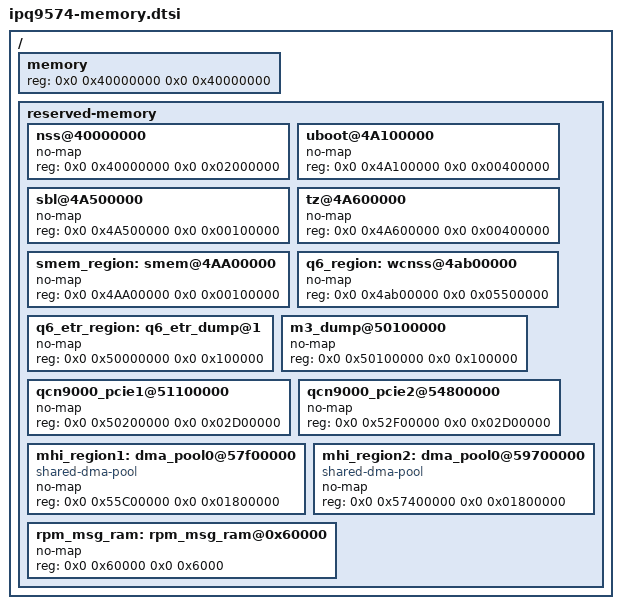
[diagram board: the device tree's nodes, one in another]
// SPDX-License-Identifier: (GPL-2.0+ OR BSD-3-Clause)
/*
 * IPQ9048 Memory device tree source
 *
 * Copyright (c) 2021 The Linux Foundation. All rights reserved.
 */

/ {

	/*		  Default Profile
	 * +=========+==============+========================+
	 * |        |              |                         |
	 * | Region | Start Offset |          Size           |
	 * |        |              |                         |
	 * +--------+--------------+-------------------------+
	 * |        |              |                         |
	 * |  NSS   |  0x40000000  |          32MB           |
	 * |        |              |                         |
	 * +--------+--------------+-------------------------+
	 * |        |              |                         |
	 * |        |              |                         |
	 * |        |              |                         |
	 * |        |              |                         |
	 * | Linux  |  0x42000000  |         129MB           |
	 * |        |              |                         |
	 * |        |              |                         |
	 * |        |              |                         |
	 * +--------+--------------+-------------------------+
	 * |        |              |                         |
	 * | uboot  |  0x4A100000  |           4MB           |
	 * |        |              |                         |
	 * +--------+--------------+-------------------------+
	 * |  SBL   |  0x4A500000  |           1MB           |
	 * +--------+--------------+-------------------------+
	 * |        |              |                         |
	 * | TZ+HYP |  0x4A600000  |           4MB           |
	 * |        |              |                         |
	 * +--------+--------------+-------------------------+
	 * |  smem  |  0x4AA00000  |           1MB           |
	 * +--------+--------------+-------------------------+
	 * |        |              |                         |
	 * |        |              |                         |
	 * | WLAN   |              |                         |
	 * |   Q6   |  0x4AB00000  |          85MB           |
	 * |        |              |                         |
	 * |        |              |                         |
	 * +--------+--------------+-------------------------+
	 * | WLAN   |              |                         |
	 * | Q6 ETR |  0x50000000  |           1MB           |
	 * | Region |              |                         |
	 * +--------+--------------+-------------------------+
	 * | M3 Dump|  0x50100000  |           1MB           |
	 * +--------+--------------+-------------------------+
	 * |        |              |                         |
	 * |  Pine1 |  0x50200000  |          45MB           |
	 * |        |              |                         |
	 * +--------+--------------+-------------------------+
	 * |        |              |                         |
	 * |  Pine2 |  0x52F00000  |          45MB           |
	 * |        |              |                         |
	 * +--------+--------------+-------------------------+
	 * |        |              |                         |
	 * |  MHI1  |  0x55C00000  |          24MB           |
	 * |        |              |                         |
	 * +--------+--------------+-------------------------+
	 * |        |              |                         |
	 * |  MHI2  |  0x57400000  |          24MB           |
	 * |        |              |                         |
	 * +=================================================+
	 * |                                                 |
	 * |                                                 |
	 * |                                                 |
	 * |            Rest of memory for Linux             |
	 * |                                                 |
	 * |                                                 |
	 * |                                                 |
	 * +=================================================+
	 */

	memory {
		device_type = "memory";
		reg = <0x0 0x40000000 0x0 0x40000000>;
	};

	reserved-memory {
		#address-cells = <2>;
		#size-cells = <2>;
		ranges;

		nss@40000000 {
			no-map;
			reg = <0x0 0x40000000 0x0 0x02000000>;
		};

		uboot@4A100000 {
			no-map;
			reg = <0x0 0x4A100000 0x0 0x00400000>;
		};

		sbl@4A500000 {
			no-map;
			reg = <0x0 0x4A500000 0x0 0x00100000>;
		};

		tz@4A600000 {
			no-map;
			reg = <0x0 0x4A600000 0x0 0x00400000>;
		};

		smem_region: smem@4AA00000 {
			no-map;
			reg = <0x0 0x4AA00000 0x0 0x00100000>;
		};

		q6_region: wcnss@4ab00000 {
			no-map;
			reg = <0x0 0x4ab00000 0x0 0x05500000>;
		};

		q6_etr_region: q6_etr_dump@1 {
			no-map;
			reg = <0x0 0x50000000 0x0 0x100000>;
		};

		m3_dump@50100000 {
			no-map;
			reg = <0x0 0x50100000 0x0 0x100000>;
		};

		qcn9000_pcie1@51100000 {
			no-map;
			reg = <0x0 0x50200000 0x0 0x02D00000>;
		};

		qcn9000_pcie2@54800000 {
			no-map;
			reg = <0x0 0x52F00000 0x0 0x02D00000>;
		};

		mhi_region1: dma_pool0@57f00000 {
			compatible = "shared-dma-pool";
			no-map;
			reg = <0x0 0x55C00000 0x0 0x01800000>;
		};

		mhi_region2: dma_pool0@59700000 {
			compatible = "shared-dma-pool";
			no-map;
			reg = <0x0 0x57400000 0x0 0x01800000>;
		};

		rpm_msg_ram: rpm_msg_ram@0x60000 {
			no-map;
			reg = <0x0 0x60000 0x0 0x6000>;
		};
	};
};
